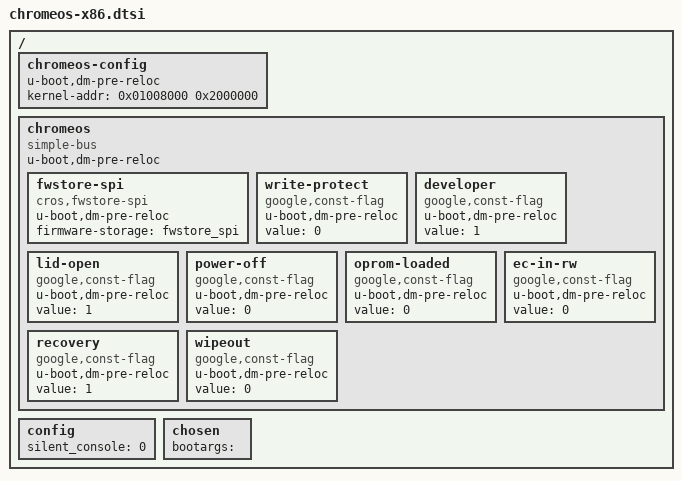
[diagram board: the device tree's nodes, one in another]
/*
 * Copyright (c) 2012 The Chromium OS Authors. All rights reserved.
 * Use of this source code is governed by a BSD-style license that can be
 * found in the LICENSE file.
 */

/*
 * This file holds Chrome OS-specific options, kept within a chromeos-config
 */

/ {
	chromeos-config {
		u-boot,dm-pre-reloc;
		/* Kernel start address and size */
		kernel-addr = <0x01008000 0x2000000>;

	};

	chromeos {
		u-boot,dm-pre-reloc;
		compatible = "simple-bus";
		fwstore-spi {
			u-boot,dm-pre-reloc;
			compatible = "cros,fwstore-spi";
			firmware-storage = <&fwstore_spi>;
		};
		write-protect {
			u-boot,dm-pre-reloc;
			compatible = "google,const-flag";
			value = <0>;
		};
		developer {
			u-boot,dm-pre-reloc;
			compatible = "google,const-flag";
			value = <1>;
		};
		lid-open {
			u-boot,dm-pre-reloc;
			compatible = "google,const-flag";
			value = <1>;
		};
		power-off {
			u-boot,dm-pre-reloc;
			compatible = "google,const-flag";
			value = <0>;
		};
		oprom-loaded {
			u-boot,dm-pre-reloc;
			compatible = "google,const-flag";
			value = <0>;
		};
		ec-in-rw {
			u-boot,dm-pre-reloc;
			compatible = "google,const-flag";
			value = <0>;
		};
		recovery {
			u-boot,dm-pre-reloc;
			compatible = "google,const-flag";
			value = <1>;
		};
		wipeout {
			u-boot,dm-pre-reloc;
			compatible = "google,const-flag";
			value = <0>;
		};
	};

	config {
		silent_console = <0>;
	};

	chosen {
		bootargs = "";
	};
};
